VERSION ""

NS_ :

BS_:

BU_: HV500_commands HV500_controller HV500_commands HV500_controller

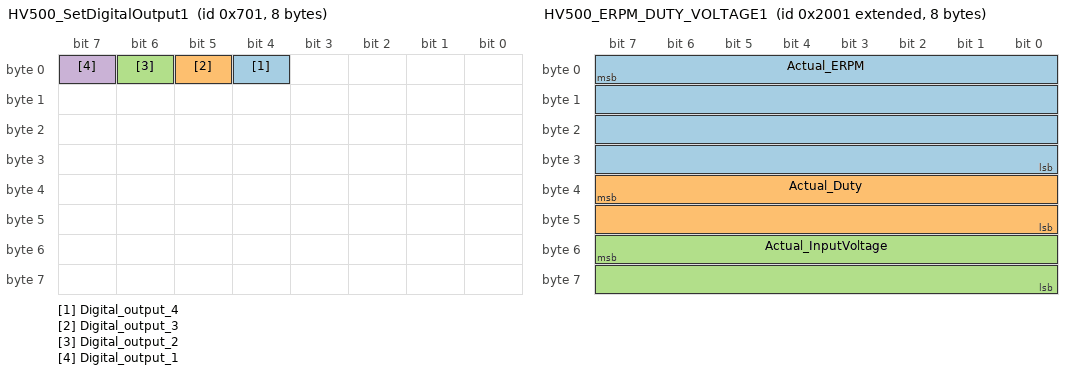
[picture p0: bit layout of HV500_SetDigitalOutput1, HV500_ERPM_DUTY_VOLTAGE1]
BO_ 1793 HV500_SetDigitalOutput1: 8 Vector__XXX
 SG_ Digital_output_4 : 4|1@0+ (1,0) [0|1] "" Vector__XXX
 SG_ Digital_output_3 : 5|1@0+ (1,0) [0|1] "" Vector__XXX
 SG_ Digital_output_2 : 6|1@0+ (1,0) [0|1] "" Vector__XXX
 SG_ Digital_output_1 : 7|1@0+ (1,0) [0|1] "" Vector__XXX

BO_ 2147491841 HV500_ERPM_DUTY_VOLTAGE1: 8 HV500_controller
 SG_ Actual_ERPM : 7|32@0- (1,0) [-214748000|214748000] "ERPM"  HV500_commands
 SG_ Actual_Duty : 39|16@0- (0.1,0) [-3276|3276] "%"  HV500_commands
 SG_ Actual_InputVoltage : 55|16@0- (1,0) [-32768|32767] "V"  HV500_commands

BO_ 2147492097 HV500_AC_DC_current1: 8 HV500_controller
 SG_ Actual_ACCurrent : 7|16@0- (0.1,0) [-3276|3276] "Apk"  HV500_commands
 SG_ Actual_DCCurrent : 23|16@0- (0.1,0) [-3276|3276] "A"  HV500_commands

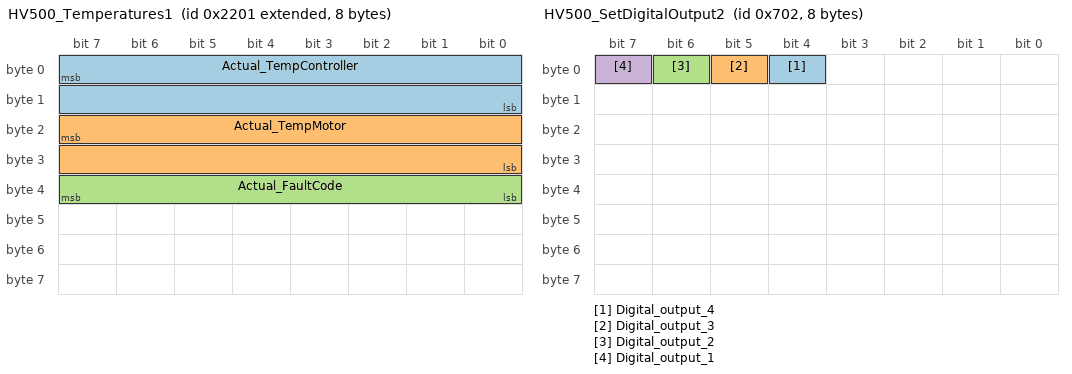
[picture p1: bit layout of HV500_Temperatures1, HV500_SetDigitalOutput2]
BO_ 2147492353 HV500_Temperatures1: 8 HV500_controller
 SG_ Actual_TempController : 7|16@0- (0.1,0) [-3276|3276] "C"  HV500_commands
 SG_ Actual_TempMotor : 23|16@0- (0.1,0) [-3276|3276] "C"  HV500_commands
 SG_ Actual_FaultCode : 39|8@0+ (1,0) [0|255] ""  HV500_commands

BO_ 2147492609 HV500_FOC1: 8 HV500_controller
 SG_ Actual_FOC_id : 7|32@0- (0.01,0) [-2147480000|2147480000] "Apk"  HV500_commands
 SG_ Actual_FOC_iq : 39|32@0- (0.01,0) [-2147480000|2147480000] "Apk"  HV500_commands

BO_ 2147492865 HV500_MISC1: 8 HV500_controller
 SG_ Actual_Throttle : 7|8@0- (1,0) [-128|127] "%"  HV500_commands
 SG_ Actual_Brake : 15|8@0- (1,0) [-128|127] "%"  HV500_commands
 SG_ Digital_input_1 : 16|1@0+ (1,0) [0|1] ""  HV500_commands
 SG_ Digital_input_2 : 17|1@0+ (1,0) [0|1] ""  HV500_commands
 SG_ Digital_input_3 : 18|1@0+ (1,0) [0|1] ""  HV500_commands
 SG_ Digital_input_4 : 19|1@0+ (1,0) [0|1] ""  HV500_commands
 SG_ Digital_output_1 : 20|1@0+ (1,0) [0|1] ""  HV500_commands
 SG_ Digital_output_2 : 21|1@0+ (1,0) [0|1] ""  HV500_commands
 SG_ Digital_output_3 : 22|1@0+ (1,0) [0|1] ""  HV500_commands
 SG_ Digital_output_4 : 23|1@0+ (1,0) [0|1] ""  HV500_commands
 SG_ Drive_enable : 31|8@0+ (1,0) [0|1] ""  HV500_commands
 SG_ Capacitor_temp_limit : 32|1@0+ (1,0) [0|1] ""  HV500_commands
 SG_ DC_current_limit : 33|1@0+ (1,0) [0|1] ""  HV500_commands
 SG_ Drive_enable_limit : 34|1@0+ (1,0) [0|1] ""  HV500_commands
 SG_ IGBT_accel_limit : 35|1@0+ (1,0) [0|1] ""  HV500_commands
 SG_ IGBT_temp_limit : 36|1@0+ (1,0) [0|1] ""  HV500_commands
 SG_ Input_voltage_limit : 37|1@0+ (1,0) [0|1] ""  HV500_commands
 SG_ Motor_accel_limit : 38|1@0+ (1,0) [0|1] ""  HV500_commands
 SG_ Motor_temp_limit : 39|1@0+ (1,0) [0|1] ""  HV500_commands
 SG_ RPM_min_limit : 40|1@0+ (1,0) [0|1] ""  HV500_commands
 SG_ RPM_max_limit : 41|1@0+ (1,0) [0|1] ""  HV500_commands
 SG_ Power_limit : 42|1@0+ (1,0) [0|1] ""  HV500_commands
 SG_ CAN_map_version : 63|8@0+ (0.1,0) [0|255] "Version"  HV500_commands

BO_ 2147486721 HV500_SetDriveEnable1: 8 HV500_commands
 SG_ CMD_DriveEnable : 7|8@0+ (1,0) [0|1] ""  HV500_controller

BO_ 2147483905 HV500_SetAcCurrent1: 8 HV500_commands
 SG_ CMD_TargetAcCurrent : 7|16@0- (0.1,0) [-1000|1000] "A"  HV500_controller

BO_ 2147484161 HV500_SetBrakeCurrent1: 8 HV500_commands
 SG_ CMD_TargetBrakeCurrent : 7|16@0- (0.1,0) [0|1000] "A"  HV500_controller

BO_ 2147484417 HV500_SetERPM1: 8 HV500_commands
 SG_ CMD_TargetSpeed : 7|32@0- (1,0) [-2147480000|2147480000] "ERPM"  HV500_controller

BO_ 2147484673 HV500_SetPosition1: 8 HV500_commands
 SG_ CMD_TargetPosition : 7|16@0- (0.1,0) [0|360] "degree"  HV500_controller

BO_ 2147484929 HV500_SetRelCurrent1: 8 HV500_commands
 SG_ CMD_TargetRelativeCurrent : 7|16@0- (0.1,0) [-100|100] "%"  HV500_controller

BO_ 2147485185 HV500_SetRelBrakeCurrent1: 8 HV500_commands
 SG_ CMD_TargeRelativeBrakeCurrent : 7|16@0- (0.1,0) [0|100] "%"  HV500_controller

BO_ 2147485697 HV500_SetMaxAcCurrent1: 8 HV500_commands
 SG_ CMD_MaxAcCurrent : 7|16@0- (0.1,0) [0|500] "A"  HV500_controller

BO_ 2147485953 HV500_SetMaxAcBrakeCurrent1: 8 HV500_commands
 SG_ CMD_MaxAcBrakeCurrent : 7|16@0- (0.1,0) [0|500] "A"  HV500_controller

BO_ 2147486209 HV500_SetMaxDcCurrent1: 8 HV500_commands
 SG_ CMD_MaxDcCurrent : 7|16@0- (0.1,0) [0|350] "A"  HV500_controller

BO_ 2147486465 HV500_SetMaxDcBrakeCurrent1: 8 HV500_commands
 SG_ CMD_MaxDcBrakeCurrent : 7|16@0- (0.1,0) [0|350] "A"  HV500_controller

BO_ 1794 HV500_SetDigitalOutput2: 8 Vector__XXX
 SG_ Digital_output_4 : 4|1@0+ (1,0) [0|1] "" Vector__XXX
 SG_ Digital_output_3 : 5|1@0+ (1,0) [0|1] "" Vector__XXX
 SG_ Digital_output_2 : 6|1@0+ (1,0) [0|1] "" Vector__XXX
 SG_ Digital_output_1 : 7|1@0+ (1,0) [0|1] "" Vector__XXX

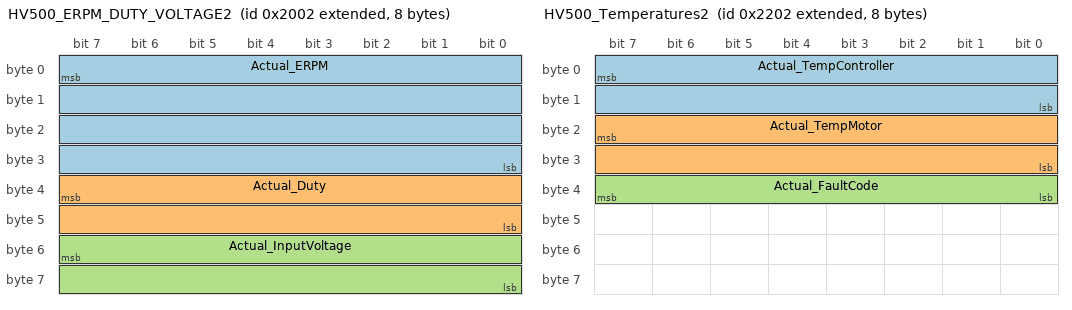
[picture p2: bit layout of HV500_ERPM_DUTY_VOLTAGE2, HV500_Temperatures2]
BO_ 2147491842 HV500_ERPM_DUTY_VOLTAGE2: 8 HV500_controller
 SG_ Actual_ERPM : 7|32@0- (1,0) [-214748000|214748000] "ERPM"  HV500_commands
 SG_ Actual_Duty : 39|16@0- (0.1,0) [-3276|3276] "%"  HV500_commands
 SG_ Actual_InputVoltage : 55|16@0- (1,0) [-32768|32767] "V"  HV500_commands

BO_ 2147492098 HV500_AC_DC_current2: 8 HV500_controller
 SG_ Actual_ACCurrent : 7|16@0- (0.1,0) [-3276|3276] "Apk"  HV500_commands
 SG_ Actual_DCCurrent : 23|16@0- (0.1,0) [-3276|3276] "A"  HV500_commands

BO_ 2147492354 HV500_Temperatures2: 8 HV500_controller
 SG_ Actual_TempController : 7|16@0- (0.1,0) [-3276|3276] "C"  HV500_commands
 SG_ Actual_TempMotor : 23|16@0- (0.1,0) [-3276|3276] "C"  HV500_commands
 SG_ Actual_FaultCode : 39|8@0+ (1,0) [0|255] ""  HV500_commands

BO_ 2147492610 HV500_FOC2: 8 HV500_controller
 SG_ Actual_FOC_id : 7|32@0- (0.01,0) [-2147480000|2147480000] "Apk"  HV500_commands
 SG_ Actual_FOC_iq : 39|32@0- (0.01,0) [-2147480000|2147480000] "Apk"  HV500_commands

BO_ 2147492866 HV500_MISC2: 8 HV500_controller
 SG_ Actual_Throttle : 7|8@0- (1,0) [-128|127] "%"  HV500_commands
 SG_ Actual_Brake : 15|8@0- (1,0) [-128|127] "%"  HV500_commands
 SG_ Digital_input_1 : 16|1@0+ (1,0) [0|1] ""  HV500_commands
 SG_ Digital_input_2 : 17|1@0+ (1,0) [0|1] ""  HV500_commands
 SG_ Digital_input_3 : 18|1@0+ (1,0) [0|1] ""  HV500_commands
 SG_ Digital_input_4 : 19|1@0+ (1,0) [0|1] ""  HV500_commands
 SG_ Digital_output_1 : 20|1@0+ (1,0) [0|1] ""  HV500_commands
 SG_ Digital_output_2 : 21|1@0+ (1,0) [0|1] ""  HV500_commands
 SG_ Digital_output_3 : 22|1@0+ (1,0) [0|1] ""  HV500_commands
 SG_ Digital_output_4 : 23|1@0+ (1,0) [0|1] ""  HV500_commands
 SG_ Drive_enable : 31|8@0+ (1,0) [0|1] ""  HV500_commands
 SG_ Capacitor_temp_limit : 32|1@0+ (1,0) [0|1] ""  HV500_commands
 SG_ DC_current_limit : 33|1@0+ (1,0) [0|1] ""  HV500_commands
 SG_ Drive_enable_limit : 34|1@0+ (1,0) [0|1] ""  HV500_commands
 SG_ IGBT_accel_limit : 35|1@0+ (1,0) [0|1] ""  HV500_commands
 SG_ IGBT_temp_limit : 36|1@0+ (1,0) [0|1] ""  HV500_commands
 SG_ Input_voltage_limit : 37|1@0+ (1,0) [0|1] ""  HV500_commands
 SG_ Motor_accel_limit : 38|1@0+ (1,0) [0|1] ""  HV500_commands
 SG_ Motor_temp_limit : 39|1@0+ (1,0) [0|1] ""  HV500_commands
 SG_ RPM_min_limit : 40|1@0+ (1,0) [0|1] ""  HV500_commands
 SG_ RPM_max_limit : 41|1@0+ (1,0) [0|1] ""  HV500_commands
 SG_ Power_limit : 42|1@0+ (1,0) [0|1] ""  HV500_commands
 SG_ CAN_map_version : 63|8@0+ (0.1,0) [0|255] "Version"  HV500_commands

BO_ 2147486722 HV500_SetDriveEnable2: 8 HV500_commands
 SG_ CMD_DriveEnable : 7|8@0+ (1,0) [0|1] ""  HV500_controller

BO_ 2147483906 HV500_SetAcCurrent2: 8 HV500_commands
 SG_ CMD_TargetAcCurrent : 7|16@0- (0.1,0) [-1000|1000] "A"  HV500_controller

BO_ 2147484162 HV500_SetBrakeCurrent2: 8 HV500_commands
 SG_ CMD_TargetBrakeCurrent : 7|16@0- (0.1,0) [0|1000] "A"  HV500_controller

BO_ 2147484418 HV500_SetERPM2: 8 HV500_commands
 SG_ CMD_TargetSpeed : 7|32@0- (1,0) [-2147480000|2147480000] "ERPM"  HV500_controller

BO_ 2147484674 HV500_SetPosition2: 8 HV500_commands
 SG_ CMD_TargetPosition : 7|16@0- (0.1,0) [0|360] "degree"  HV500_controller

BO_ 2147484930 HV500_SetRelCurrent2: 8 HV500_commands
 SG_ CMD_TargetRelativeCurrent : 7|16@0- (0.1,0) [-100|100] "%"  HV500_controller

BO_ 2147485186 HV500_SetRelBrakeCurrent2: 8 HV500_commands
 SG_ CMD_TargeRelativeBrakeCurrent : 7|16@0- (0.1,0) [0|100] "%"  HV500_controller

BO_ 2147485698 HV500_SetMaxAcCurrent2: 8 HV500_commands
 SG_ CMD_MaxAcCurrent : 7|16@0- (0.1,0) [0|500] "A"  HV500_controller

BO_ 2147485954 HV500_SetMaxAcBrakeCurrent2: 8 HV500_commands
 SG_ CMD_MaxAcBrakeCurrent : 7|16@0- (0.1,0) [0|500] "A"  HV500_controller

BO_ 2147486210 HV500_SetMaxDcCurrent2: 8 HV500_commands
 SG_ CMD_MaxDcCurrent : 7|16@0- (0.1,0) [0|350] "A"  HV500_controller

BO_ 2147486466 HV500_SetMaxDcBrakeCurrent2: 8 HV500_commands
 SG_ CMD_MaxDcBrakeCurrent : 7|16@0- (0.1,0) [0|350] "A"  HV500_controller

CM_ BO_ 2147491841 "Node ID: 20";
CM_ SG_ 2147491841 Actual_ERPM "Electrical RPM
Equation: ERPM = Motor RPM * number of the motor pole pairs.";
CM_ SG_ 2147491841 Actual_Duty "The controller duty cycle. The sign of this value will represent whether the motor is running(positive) current or regenerating (negative) current.";
CM_ SG_ 2147491841 Actual_InputVoltage "Input voltage is the DC voltage.";
CM_ BO_ 2147492097 "Node ID: 20";
CM_ SG_ 2147492097 Actual_ACCurrent "The motor current. The sign of this value represents whether the motor is running(positive) current or regenerating (negative) current.";
CM_ SG_ 2147492097 Actual_DCCurrent "DC Current: Current on DC side. The sign of this value represents whether the motor is running(positive) current or regenerating (negative) current.";
CM_ BO_ 2147492353 "Node ID: 20";
CM_ SG_ 2147492353 Actual_TempController "Temperature of the inverter semiconductors.";
CM_ SG_ 2147492353 Actual_TempMotor "Temperature of the motor measured by the inverter.";
CM_ SG_ 2147492353 Actual_FaultCode "Fault codes.";
CM_ BO_ 2147492609 "Node ID: 20";
CM_ SG_ 2147492609 Actual_FOC_id "FOC algorithm component Id.";
CM_ SG_ 2147492609 Actual_FOC_iq "FOC algorithm component Iq";
CM_ BO_ 2147492865 "Node ID: 20";
CM_ SG_ 2147492865 Actual_Throttle "Throttle signal derived from analog inputs or CAN2.";
CM_ SG_ 2147492865 Actual_Brake "Brake signal derived from analog inputs or CAN2.";
CM_ SG_ 2147492865 CAN_map_version "Indicates the CAN map version. For ex: 23 -> 2,3 (V2,3)";
CM_ BO_ 2147486721 "Node ID: 20";
CM_ BO_ 2147483905 "Node ID: 20";
CM_ BO_ 2147484161 "Node ID: 20";
CM_ BO_ 2147484417 "Node ID: 20";
CM_ BO_ 2147484673 "Node ID: 20";
CM_ BO_ 2147484929 "Node ID: 20";
CM_ BO_ 2147485185 "Node ID: 20";
CM_ BO_ 2147485697 "Node ID: 20";
CM_ BO_ 2147485953 "Node ID: 20";
CM_ BO_ 2147486209 "Node ID: 20";
CM_ BO_ 2147486465 "Node ID: 20";
CM_ BO_ 2147491842 "Node ID: 20";
CM_ SG_ 2147491842 Actual_ERPM "Electrical RPM
Equation: ERPM = Motor RPM * number of the motor pole pairs.";
CM_ SG_ 2147491842 Actual_Duty "The controller duty cycle. The sign of this value will represent whether the motor is running(positive) current or regenerating (negative) current.";
CM_ SG_ 2147491842 Actual_InputVoltage "Input voltage is the DC voltage.";
CM_ BO_ 2147492098 "Node ID: 20";
CM_ SG_ 2147492098 Actual_ACCurrent "The motor current. The sign of this value represents whether the motor is running(positive) current or regenerating (negative) current.";
CM_ SG_ 2147492098 Actual_DCCurrent "DC Current: Current on DC side. The sign of this value represents whether the motor is running(positive) current or regenerating (negative) current.";
CM_ BO_ 2147492354 "Node ID: 20";
CM_ SG_ 2147492354 Actual_TempController "Temperature of the inverter semiconductors.";
CM_ SG_ 2147492354 Actual_TempMotor "Temperature of the motor measured by the inverter.";
CM_ SG_ 2147492354 Actual_FaultCode "Fault codes.";
CM_ BO_ 2147492610 "Node ID: 20";
CM_ SG_ 2147492610 Actual_FOC_id "FOC algorithm component Id.";
CM_ SG_ 2147492610 Actual_FOC_iq "FOC algorithm component Iq";
CM_ BO_ 2147492866 "Node ID: 20";
CM_ SG_ 2147492866 Actual_Throttle "Throttle signal derived from analog inputs or CAN2.";
CM_ SG_ 2147492866 Actual_Brake "Brake signal derived from analog inputs or CAN2.";
CM_ SG_ 2147492866 CAN_map_version "Indicates the CAN map version. For ex: 23 -> 2,3 (V2,3)";
CM_ BO_ 2147486722 "Node ID: 20";
CM_ BO_ 2147483906 "Node ID: 20";
CM_ BO_ 2147484162 "Node ID: 20";
CM_ BO_ 2147484418 "Node ID: 20";
CM_ BO_ 2147484674 "Node ID: 20";
CM_ BO_ 2147484930 "Node ID: 20";
CM_ BO_ 2147485186 "Node ID: 20";
CM_ BO_ 2147485698 "Node ID: 20";
CM_ BO_ 2147485954 "Node ID: 20";
CM_ BO_ 2147486210 "Node ID: 20";
CM_ BO_ 2147486466 "Node ID: 20";
BA_DEF_ BO_  "GenMsgSendType" ENUM  "Cyclic","IfActive";
BA_DEF_ BO_  "GenMsgCycleTime" INT 0 0;
BA_DEF_ BO_  "GenMsgBackgroundColor" STRING ;
BA_DEF_ BO_  "GenMsgForegroundColor" STRING ;
BA_DEF_DEF_  "GenMsgSendType" "Cyclic";
BA_DEF_DEF_  "GenMsgCycleTime" 0;
BA_DEF_DEF_  "GenMsgBackgroundColor" "#ffffff";
BA_DEF_DEF_  "GenMsgForegroundColor" "#000000";
BA_ "GenMsgCycleTime" BO_ 2147491841 100;
BA_ "GenMsgCycleTime" BO_ 2147492097 100;
BA_ "GenMsgCycleTime" BO_ 2147492353 100;
BA_ "GenMsgCycleTime" BO_ 2147492609 100;
BA_ "GenMsgCycleTime" BO_ 2147492865 100;
BA_ "GenMsgCycleTime" BO_ 2147486721 100;
BA_ "GenMsgCycleTime" BO_ 2147483905 100;
BA_ "GenMsgCycleTime" BO_ 2147484161 100;
BA_ "GenMsgCycleTime" BO_ 2147484417 100;
BA_ "GenMsgCycleTime" BO_ 2147484673 100;
BA_ "GenMsgCycleTime" BO_ 2147484929 100;
BA_ "GenMsgCycleTime" BO_ 2147485185 100;
BA_ "GenMsgCycleTime" BO_ 2147485697 100;
BA_ "GenMsgCycleTime" BO_ 2147485953 100;
BA_ "GenMsgCycleTime" BO_ 2147486209 100;
BA_ "GenMsgCycleTime" BO_ 2147486465 100;
BA_ "GenMsgCycleTime" BO_ 2147491842 100;
BA_ "GenMsgCycleTime" BO_ 2147492098 100;
BA_ "GenMsgCycleTime" BO_ 2147492354 100;
BA_ "GenMsgCycleTime" BO_ 2147492610 100;
BA_ "GenMsgCycleTime" BO_ 2147492866 100;
BA_ "GenMsgCycleTime" BO_ 2147486722 100;
BA_ "GenMsgCycleTime" BO_ 2147483906 100;
BA_ "GenMsgCycleTime" BO_ 2147484162 100;
BA_ "GenMsgCycleTime" BO_ 2147484418 100;
BA_ "GenMsgCycleTime" BO_ 2147484674 100;
BA_ "GenMsgCycleTime" BO_ 2147484930 100;
BA_ "GenMsgCycleTime" BO_ 2147485186 100;
BA_ "GenMsgCycleTime" BO_ 2147485698 100;
BA_ "GenMsgCycleTime" BO_ 2147485954 100;
BA_ "GenMsgCycleTime" BO_ 2147486210 100;
BA_ "GenMsgCycleTime" BO_ 2147486466 100;
VAL_ 1793 Digital_output_4 0 "Output_4_disabled" 1 "Output_4_enabled" ;
VAL_ 1793 Digital_output_3 0 "Output_3_disabled" 1 "Output_3_enabled" ;
VAL_ 1793 Digital_output_2 0 "Output_2_disabled" 1 "Output_2_enabled" ;
VAL_ 1793 Digital_output_1 0 "Output_1_disabled" 1 "Output_1_enabled" ;
VAL_ 2147492353 Actual_FaultCode 0 "NO_FAULT" 1 "OVERVOLTAGE_-_The_input_voltage_is_higher_than_the_set_maximum" 2 "UNDERVOLTAGE_-_The_input_voltage_is_lower_than_the_set_minimum" 3 "DRV_ERROR_-_Transistor_or_transistor_drive_error" 4 "ABSOLUTE_MAX_OVERCURRENT_-_The_AC_current_is_higher_than_the_set_absolute_maximum_current" 5 "CONTROLLER_OVERTEMPERATURE_-_The_controller_temperature_is_higher_than_the_set_maximum" 6 "MOTOR_OVERTEMPERATURE_-_The_motor_temperature_is_higher_than_the_set_maximum" 7 "SENSOR_WIRE_FAULT_-_Something_went_wrong_with_the_sensor_differential_signals" 8 "SENSOR_GENERAL_FAULT_-_An_error_occurred_while_processing_the_sensor_signals" 9 "CAN_COMMAND_ERROR_-_CAN_message_received_contains_parameter_out_of_boundaries" 10 "ANALOG_INPUT_ERROR_–_Redundant_output_out_of_range" ;
VAL_ 2147492865 Digital_input_1 0 "Input_1_disabled" 1 "Input_1_enabled" ;
VAL_ 2147492865 Digital_input_2 0 "Input_2_enabled" 1 "Input_2_enabled" ;
VAL_ 2147492865 Digital_input_3 0 "Input_3_disabled" 1 "Input_3_enabled" ;
VAL_ 2147492865 Digital_input_4 0 "Input_4_disabled" 1 "Input_4_enabled" ;
VAL_ 2147492865 Digital_output_1 0 "Output_1_disabled" 1 "Output_1_enabled" ;
VAL_ 2147492865 Digital_output_2 0 "Output_2_disabled" 1 "Output_2_enabled" ;
VAL_ 2147492865 Digital_output_3 0 "Output_3_disabled" 1 "Output_3_enabled" ;
VAL_ 2147492865 Digital_output_4 0 "Output_4_disabled" 1 "Output_4_enabled" ;
VAL_ 2147492865 Drive_enable 0 "Drive_disabled" 1 "Drive_enabled" ;
VAL_ 2147492865 Capacitor_temp_limit 0 "Capacitor_temperature_limit_inactive" 1 "Capacitor_temperature_limit_active" ;
VAL_ 2147492865 DC_current_limit 0 "DC_current_limit_active" 1 "DC_current_limit_inactive" ;
VAL_ 2147492865 Drive_enable_limit 0 "Drive_enable_limit_inactive" 1 "Drive_enable_limit_active" ;
VAL_ 2147492865 IGBT_accel_limit 0 "IGBT_acceleration_temperature_limit_inactive" 1 "IGBT_acceleration_temperature_limit_inactive" ;
VAL_ 2147492865 IGBT_temp_limit 0 "IGBT_temperature_limit_inactive" 1 "IGBT_temperature_limit_active" ;
VAL_ 2147492865 Input_voltage_limit 0 "Input_voltage_limit_inactive" 1 "Input_voltage_limit_active" ;
VAL_ 2147492865 Motor_accel_limit 0 "Motor_acceleration_temperature_limit_inactive" 1 "Motor_acceleration_temperature_limit_active" ;
VAL_ 2147492865 Motor_temp_limit 0 "Motor_temperature_limit_inactive" 1 "Motor_temperature_limit_active" ;
VAL_ 2147492865 RPM_min_limit 0 "RPM_minimum_limit_inactive" 1 "RPM_minimum_limit_active" ;
VAL_ 2147492865 RPM_max_limit 0 "RPM_maximum_limit_inactive" 1 "RPM_maximum_limit_active" ;
VAL_ 2147492865 Power_limit 0 "Power_limit_inactive" 1 "Power_limit_active" ;
VAL_ 2147486721 CMD_DriveEnable 1 "Drive allowed" 0 "Drive_not_allowed" ;
VAL_ 1794 Digital_output_4 0 "Output_4_disabled" 1 "Output_4_enabled" ;
VAL_ 1794 Digital_output_3 0 "Output_3_disabled" 1 "Output_3_enabled" ;
VAL_ 1794 Digital_output_2 0 "Output_2_disabled" 1 "Output_2_enabled" ;
VAL_ 1794 Digital_output_1 0 "Output_1_disabled" 1 "Output_1_enabled" ;
VAL_ 2147492354 Actual_FaultCode 0 "NO_FAULT" 1 "OVERVOLTAGE_-_The_input_voltage_is_higher_than_the_set_maximum" 2 "UNDERVOLTAGE_-_The_input_voltage_is_lower_than_the_set_minimum" 3 "DRV_ERROR_-_Transistor_or_transistor_drive_error" 4 "ABSOLUTE_MAX_OVERCURRENT_-_The_AC_current_is_higher_than_the_set_absolute_maximum_current" 5 "CONTROLLER_OVERTEMPERATURE_-_The_controller_temperature_is_higher_than_the_set_maximum" 6 "MOTOR_OVERTEMPERATURE_-_The_motor_temperature_is_higher_than_the_set_maximum" 7 "SENSOR_WIRE_FAULT_-_Something_went_wrong_with_the_sensor_differential_signals" 8 "SENSOR_GENERAL_FAULT_-_An_error_occurred_while_processing_the_sensor_signals" 9 "CAN_COMMAND_ERROR_-_CAN_message_received_contains_parameter_out_of_boundaries" 10 "ANALOG_INPUT_ERROR_–_Redundant_output_out_of_range" ;
VAL_ 2147492866 Digital_input_1 0 "Input_1_disabled" 1 "Input_1_enabled" ;
VAL_ 2147492866 Digital_input_2 0 "Input_2_enabled" 1 "Input_2_enabled" ;
VAL_ 2147492866 Digital_input_3 0 "Input_3_disabled" 1 "Input_3_enabled" ;
VAL_ 2147492866 Digital_input_4 0 "Input_4_disabled" 1 "Input_4_enabled" ;
VAL_ 2147492866 Digital_output_1 0 "Output_1_disabled" 1 "Output_1_enabled" ;
VAL_ 2147492866 Digital_output_2 0 "Output_2_disabled" 1 "Output_2_enabled" ;
VAL_ 2147492866 Digital_output_3 0 "Output_3_disabled" 1 "Output_3_enabled" ;
VAL_ 2147492866 Digital_output_4 0 "Output_4_disabled" 1 "Output_4_enabled" ;
VAL_ 2147492866 Drive_enable 0 "Drive_disabled" 1 "Drive_enabled" ;
VAL_ 2147492866 Capacitor_temp_limit 0 "Capacitor_temperature_limit_inactive" 1 "Capacitor_temperature_limit_active" ;
VAL_ 2147492866 DC_current_limit 0 "DC_current_limit_active" 1 "DC_current_limit_inactive" ;
VAL_ 2147492866 Drive_enable_limit 0 "Drive_enable_limit_inactive" 1 "Drive_enable_limit_active" ;
VAL_ 2147492866 IGBT_accel_limit 0 "IGBT_acceleration_temperature_limit_inactive" 1 "IGBT_acceleration_temperature_limit_inactive" ;
VAL_ 2147492866 IGBT_temp_limit 0 "IGBT_temperature_limit_inactive" 1 "IGBT_temperature_limit_active" ;
VAL_ 2147492866 Input_voltage_limit 0 "Input_voltage_limit_inactive" 1 "Input_voltage_limit_active" ;
VAL_ 2147492866 Motor_accel_limit 0 "Motor_acceleration_temperature_limit_inactive" 1 "Motor_acceleration_temperature_limit_active" ;
VAL_ 2147492866 Motor_temp_limit 0 "Motor_temperature_limit_inactive" 1 "Motor_temperature_limit_active" ;
VAL_ 2147492866 RPM_min_limit 0 "RPM_minimum_limit_inactive" 1 "RPM_minimum_limit_active" ;
VAL_ 2147492866 RPM_max_limit 0 "RPM_maximum_limit_inactive" 1 "RPM_maximum_limit_active" ;
VAL_ 2147492866 Power_limit 0 "Power_limit_inactive" 1 "Power_limit_active" ;
VAL_ 2147486722 CMD_DriveEnable 1 "Drive allowed" 0 "Drive_not_allowed" ;
